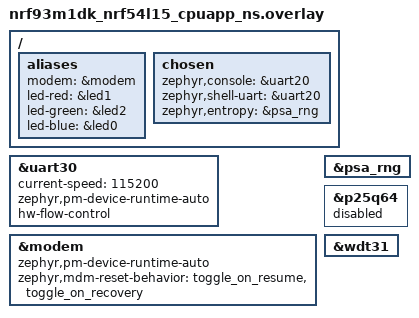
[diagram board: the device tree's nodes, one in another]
/*
 * Copyright (c) 2026 Nordic Semiconductor ASA
 *
 * SPDX-License-Identifier: LicenseRef-Nordic-5-Clause
 */

/ {
	aliases {
		modem = &modem;
		led-red = &led1;
		led-green = &led2;
		led-blue = &led0;
	};
	chosen {
		zephyr,console = &uart20;
		zephyr,shell-uart = &uart20;
		zephyr,entropy = &psa_rng;
	};
};

&uart30 {
	status = "okay";
	current-speed = <115200>;
	zephyr,pm-device-runtime-auto;
	hw-flow-control;
};

&modem {
	status = "okay";
	zephyr,pm-device-runtime-auto;
	/* A host reset leaves the modem in CMUX mode, so the init script gets no reply until
	 * the recovery reset 15 s later. Reset it on every start.
	 */
	zephyr,mdm-reset-behavior = "toggle_on_resume", "toggle_on_recovery";
	/* No CMUX runtime power save: the nRF93M1 rejects the in-band PSC command, so a slow
	 * reply such as AT%WIFISCAN gets lost and the PPP link drops with NO CARRIER.
	 */
};

&psa_rng {
	status = "okay";
};

&p25q64 {
	status = "disabled";
};

/* Non-secure hardware watchdog, fallback for CONFIG_TASK_WDT_HW_FALLBACK. */
&wdt31 {
	status = "okay";
};

#include "nrf93m1dk_partitions.dtsi"
